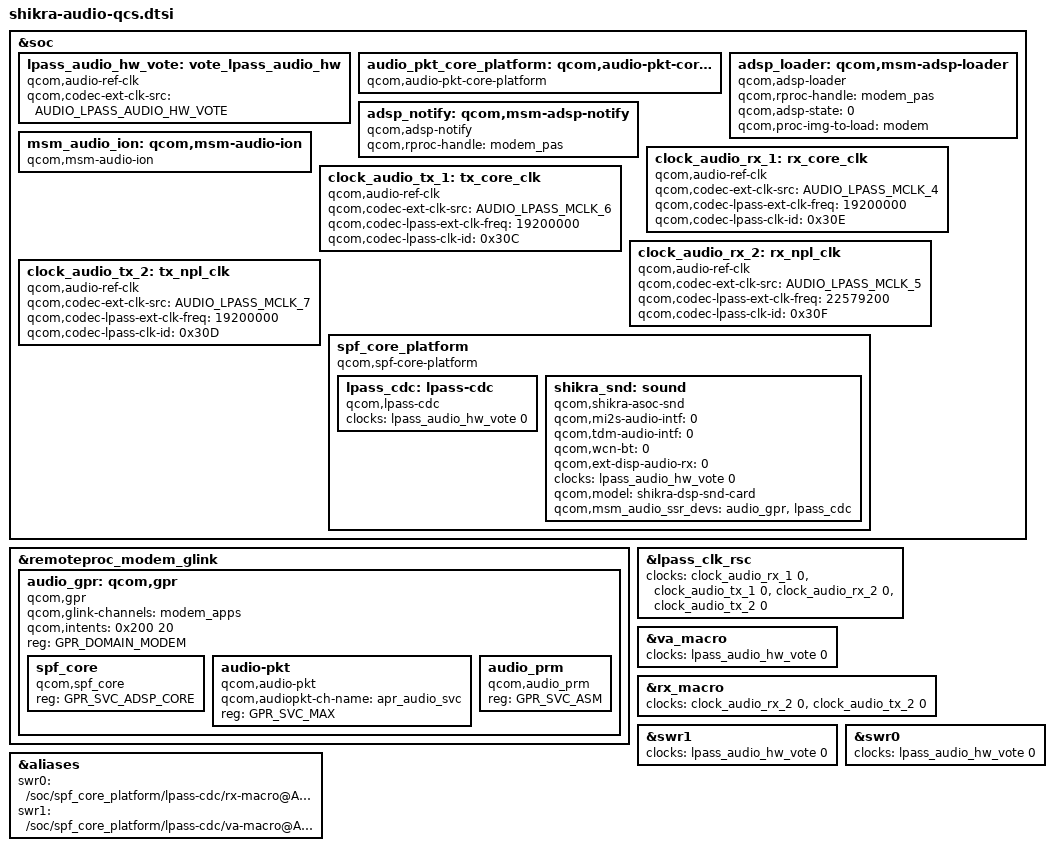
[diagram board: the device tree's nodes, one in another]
/*
 * Copyright (c) Qualcomm Technologies, Inc. and/or its subsidiaries.
 * SPDX-License-Identifier: BSD-3-Clause
*/

#include <bindings/qcom,gpr.h>
#include <bindings/qcom,audio-ext-clk.h>

&soc {
	lpass_audio_hw_vote: vote_lpass_audio_hw {
		compatible = "qcom,audio-ref-clk";
		qcom,codec-ext-clk-src = <AUDIO_LPASS_AUDIO_HW_VOTE>;
		#clock-cells = <1>;
	};

	audio_pkt_core_platform: qcom,audio-pkt-core-platform {
		compatible = "qcom,audio-pkt-core-platform";
	};

	adsp_loader: qcom,msm-adsp-loader {
		status = "okay";
		compatible = "qcom,adsp-loader";
		qcom,rproc-handle = <&modem_pas>;
		qcom,adsp-state = <0>;
		qcom,proc-img-to-load = "modem";
	};

	adsp_notify: qcom,msm-adsp-notify {
		status = "okay";
		compatible = "qcom,adsp-notify";
		qcom,rproc-handle = <&modem_pas>;
	};

	msm_audio_ion: qcom,msm-audio-ion {
		compatible = "qcom,msm-audio-ion";
	};

	clock_audio_rx_1: rx_core_clk {
		compatible = "qcom,audio-ref-clk";
		qcom,codec-ext-clk-src = <AUDIO_LPASS_MCLK_4>;
		qcom,codec-lpass-ext-clk-freq = <19200000>;
		qcom,codec-lpass-clk-id = <0x30E>;
		#clock-cells = <1>;
	};

	clock_audio_tx_1: tx_core_clk {
		compatible = "qcom,audio-ref-clk";
		qcom,codec-ext-clk-src = <AUDIO_LPASS_MCLK_6>;
		qcom,codec-lpass-ext-clk-freq = <19200000>;
		qcom,codec-lpass-clk-id = <0x30C>;
		#clock-cells = <1>;
	};

	clock_audio_rx_2: rx_npl_clk {
		compatible = "qcom,audio-ref-clk";
		qcom,codec-ext-clk-src = <AUDIO_LPASS_MCLK_5>;
		qcom,codec-lpass-ext-clk-freq = <22579200>;
		qcom,codec-lpass-clk-id = <0x30F>;
		#clock-cells = <1>;
	};

	clock_audio_tx_2: tx_npl_clk {
		compatible = "qcom,audio-ref-clk";
		qcom,codec-ext-clk-src = <AUDIO_LPASS_MCLK_7>;
		qcom,codec-lpass-ext-clk-freq = <19200000>;
		qcom,codec-lpass-clk-id = <0x30D>;
		#clock-cells = <1>;
	};
};


&remoteproc_modem_glink {
	audio_gpr: qcom,gpr {
		compatible = "qcom,gpr";
		qcom,glink-channels = "modem_apps";
		qcom,intents = <0x200 20>;
		reg = <GPR_DOMAIN_MODEM>;

		spf_core {
			compatible = "qcom,spf_core";
			reg = <GPR_SVC_ADSP_CORE>;
		};

		audio-pkt {
			compatible = "qcom,audio-pkt";
			qcom,audiopkt-ch-name = "apr_audio_svc";
			reg = <GPR_SVC_MAX>;
		};

		audio_prm {
			compatible = "qcom,audio_prm";
			reg = <GPR_SVC_ASM>;
		};
	};
};

&soc {
	spf_core_platform: spf_core_platform {
		#address-cells = <2>;
		#size-cells = <2>;
		compatible = "qcom,spf-core-platform";

		lpass_cdc: lpass-cdc {
			compatible = "qcom,lpass-cdc";
		};

		shikra_snd: sound {
			compatible = "qcom,shikra-asoc-snd";
			qcom,mi2s-audio-intf = <0>;
			qcom,tdm-audio-intf = <0>;
			qcom,wcn-bt = <0>;
			qcom,ext-disp-audio-rx = <0>;
			clock-names = "lpass_audio_hw_vote";
			clocks = <&lpass_audio_hw_vote 0>;
		};
	};
};

#include "shikra-audio-overlay.dtsi"

&shikra_snd{
	qcom,model = "shikra-dsp-snd-card";
	qcom,msm_audio_ssr_devs = <&audio_gpr>,
					<&lpass_cdc>;
};

&lpass_cdc {
	clock-names = "lpass_audio_hw_vote";
	clocks = <&lpass_audio_hw_vote 0>;
};

&lpass_clk_rsc {
	clocks = <&clock_audio_rx_1 0>, <&clock_audio_tx_1 0>,
		<&clock_audio_rx_2 0>, <&clock_audio_tx_2 0>;
};

&va_macro{
	clock-names = "lpass_audio_hw_vote";
	clocks = <&lpass_audio_hw_vote 0>;
};

&rx_macro {
	clocks = <&clock_audio_rx_2 0>, <&clock_audio_tx_2 0>;
};

&swr1{
	clock-names = "lpass_audio_hw_vote";
	clocks = <&lpass_audio_hw_vote 0>;
};

&swr0 {
	clock-names = "lpass_audio_hw_vote";
	clocks = <&lpass_audio_hw_vote 0>;
};

&aliases {
	swr0 = "/soc/spf_core_platform/lpass-cdc/rx-macro@A040000/rx_swr_master";
	swr1 = "/soc/spf_core_platform/lpass-cdc/va-macro@A078000/va_swr_master";
};
